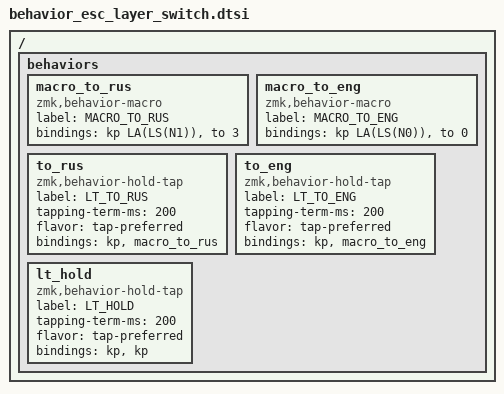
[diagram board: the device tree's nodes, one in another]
/ {
  behaviors {
    macro_to_rus: macro_to_rus {
      compatible = "zmk,behavior-macro";
      label = "MACRO_TO_RUS";
      #binding-cells = <0>;
      bindings = < &kp LA(LS(N1)) &to 3 >;
    };

    macro_to_eng: macro_to_eng {
      compatible = "zmk,behavior-macro";
      label = "MACRO_TO_ENG";
      #binding-cells = <0>;
      bindings = < &kp LA(LS(N0)) &to 0 >;
    };

    to_rus: to_rus {
      compatible = "zmk,behavior-hold-tap";
      label = "LT_TO_RUS";
      #binding-cells = <2>;
      tapping-term-ms = <200>;
      flavor = "tap-preferred";
      bindings = <&kp>, <&macro_to_rus>;
    };

    to_eng: to_eng {
      compatible = "zmk,behavior-hold-tap";
      label = "LT_TO_ENG";
      #binding-cells = <2>;
      tapping-term-ms = <200>;
      flavor = "tap-preferred";
      bindings = <&kp>, <&macro_to_eng>;
    };

    lt_hold: lt_hold {
      compatible = "zmk,behavior-hold-tap";
      label = "LT_HOLD";
      #binding-cells = <2>;
      tapping-term-ms = <200>;
      flavor = "tap-preferred";
      bindings = <&kp>, <&kp>;
    };
  };
};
